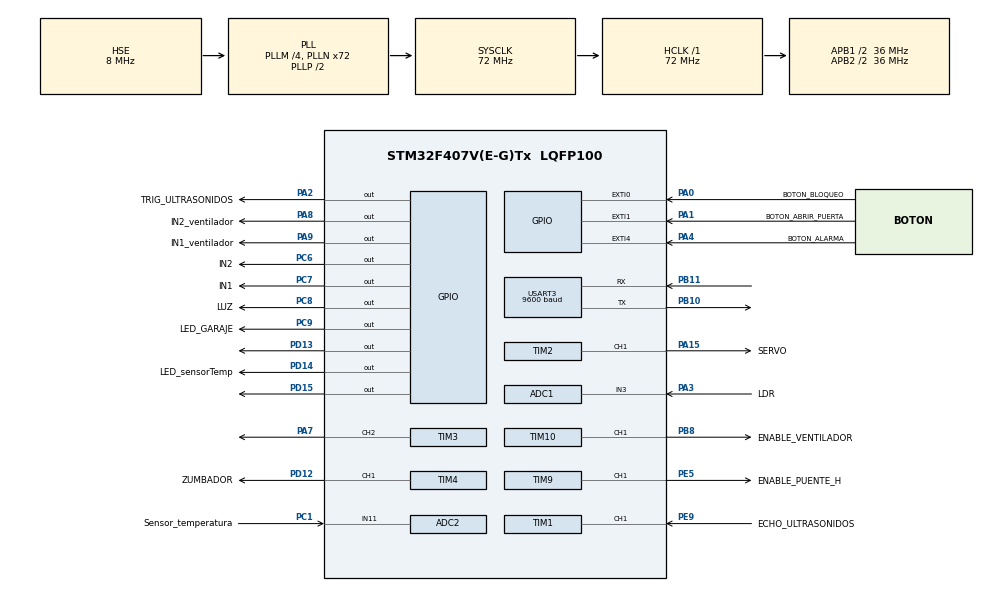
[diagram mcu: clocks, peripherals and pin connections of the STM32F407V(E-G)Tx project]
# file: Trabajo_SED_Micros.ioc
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ADC1.Channel-0\#ChannelRegularConversion=ADC_CHANNEL_3
ADC1.NbrOfConversionFlag=1
ADC1.Rank-0\#ChannelRegularConversion=1
ADC1.Resolution=ADC_RESOLUTION_8B
ADC1.SamplingTime-0\#ChannelRegularConversion=ADC_SAMPLETIME_3CYCLES
ADC1.master=1
ADC2.Channel-0\#ChannelRegularConversion=ADC_CHANNEL_11
ADC2.NbrOfConversionFlag=1
ADC2.Rank-0\#ChannelRegularConversion=1
ADC2.Resolution=ADC_RESOLUTION_8B
ADC2.SamplingTime-0\#ChannelRegularConversion=ADC_SAMPLETIME_3CYCLES
Dma.Request0=USART3_RX
Dma.USART3_RX.0.Direction=DMA_PERIPH_TO_MEMORY
Dma.USART3_RX.0.FIFOMode=DMA_FIFOMODE_DISABLE
Dma.USART3_RX.0.Instance=DMA1_Stream1
Dma.USART3_RX.0.MemDataAlignment=DMA_MDATAALIGN_BYTE
Dma.USART3_RX.0.MemInc=DMA_MINC_ENABLE
Dma.USART3_RX.0.Mode=DMA_NORMAL
Dma.USART3_RX.0.PeriphDataAlignment=DMA_PDATAALIGN_BYTE
Dma.USART3_RX.0.PeriphInc=DMA_PINC_DISABLE
Dma.USART3_RX.0.Priority=DMA_PRIORITY_LOW
Mcu.Family=STM32F4
Mcu.Name=STM32F407V(E-G)Tx
Mcu.Package=LQFP100
NVIC.ADC_IRQn=true\:0\:0\:false\:false\:true\:true\:true
NVIC.DMA1_Stream1_IRQn=true\:0\:0\:false\:false\:true\:false\:true
NVIC.EXTI0_IRQn=true\:0\:0\:false\:false\:true\:true\:true
NVIC.EXTI1_IRQn=true\:0\:0\:false\:false\:true\:true\:true
NVIC.EXTI4_IRQn=true\:0\:0\:false\:false\:true\:true\:true
NVIC.PriorityGroup=NVIC_PRIORITYGROUP_0
NVIC.TIM1_CC_IRQn=true\:0\:0\:false\:false\:true\:true\:true
NVIC.TIM2_IRQn=true\:0\:0\:false\:false\:true\:true\:true
NVIC.USART3_IRQn=true\:0\:0\:false\:false\:true\:true\:true
PA0-WKUP.GPIO_Label=BOTON_BLOQUEO
PA0-WKUP.Signal=GPXTI0
PA1.GPIO_Label=BOTON_ABRIR_PUERTA
PA1.Signal=GPXTI1
PA15.GPIO_Label=SERVO
PA15.Signal=S_TIM2_CH1_ETR
PA2.GPIO_Label=TRIG_ULTRASONIDOS
PA2.Signal=GPIO_Output
PA3.GPIO_Label=LDR
PA3.Signal=ADCx_IN3
PA4.GPIO_Label=BOTON_ALARMA
PA4.Signal=GPXTI4
PA7.Signal=S_TIM3_CH2
PA8.GPIO_Label=IN2_ventilador
PA8.Signal=GPIO_Output
PA9.GPIO_Label=IN1_ventilador
PA9.Signal=GPIO_Output
PB10.Mode=Asynchronous
PB10.Signal=USART3_TX
PB11.Mode=Asynchronous
PB11.Signal=USART3_RX
PB8.GPIO_Label=ENABLE_VENTILADOR
PB8.Signal=S_TIM10_CH1
PC1.GPIO_Label=Sensor_temperatura
PC1.Signal=ADCx_IN11
PC6.GPIO_Label=IN2
PC6.Signal=GPIO_Output
PC7.GPIO_Label=IN1
PC7.Signal=GPIO_Output
PC8.GPIO_Label=LUZ
PC8.Signal=GPIO_Output
PC9.GPIO_Label=LED_GARAJE
PC9.Signal=GPIO_Output
PD12.GPIO_Label=ZUMBADOR
PD12.Signal=S_TIM4_CH1
PD13.Signal=GPIO_Output
PD14.GPIO_Label=LED_sensorTemp
PD14.Signal=GPIO_Output
PD15.Signal=GPIO_Output
PE5.GPIO_Label=ENABLE_PUENTE_H
PE5.Signal=S_TIM9_CH1
PE9.GPIO_Label=ECHO_ULTRASONIDOS
PE9.Signal=S_TIM1_CH1
PH0-OSC_IN.Mode=HSE-External-Oscillator
PH0-OSC_IN.Signal=RCC_OSC_IN
PH1-OSC_OUT.Mode=HSE-External-Oscillator
PH1-OSC_OUT.Signal=RCC_OSC_OUT
ProjectManager.HeapSize=0x200
ProjectManager.StackSize=0x400
ProjectManager.TargetToolchain=STM32CubeIDE
RCC.48MHZClocksFreq_Value=20571428.57142857
RCC.AHBFreq_Value=72000000
RCC.APB1CLKDivider=RCC_HCLK_DIV2
RCC.APB1Freq_Value=36000000
RCC.APB1TimFreq_Value=72000000
RCC.APB2CLKDivider=RCC_HCLK_DIV2
RCC.APB2Freq_Value=36000000
RCC.APB2TimFreq_Value=72000000
RCC.CortexFreq_Value=72000000
RCC.HCLKFreq_Value=72000000
RCC.HSE_VALUE=8000000
RCC.HSI_VALUE=16000000
RCC.LSE_VALUE=32768
RCC.PLLM=4
RCC.PLLN=72
RCC.PLLQ=7
RCC.PLLSourceVirtual=RCC_PLLSOURCE_HSE
RCC.SYSCLKFreq_VALUE=72000000
RCC.SYSCLKSource=RCC_SYSCLKSOURCE_PLLCLK
RCC.VCOOutputFreq_Value=144000000
SH.ADCx_IN11.0=ADC2_IN11,IN11
SH.ADCx_IN3.0=ADC1_IN3,IN3
SH.S_TIM10_CH1.0=TIM10_CH1,PWM Generation1 CH1
SH.S_TIM1_CH1.0=TIM1_CH1,Input_Capture1_from_TI1
SH.S_TIM2_CH1_ETR.0=TIM2_CH1,PWM Generation1 CH1
SH.S_TIM3_CH2.0=TIM3_CH2,PWM Generation2 CH2
SH.S_TIM4_CH1.0=TIM4_CH1,PWM Generation1 CH1
SH.S_TIM9_CH1.0=TIM9_CH1,PWM Generation1 CH1
TIM1.Channel-Input_Capture1_from_TI1=TIM_CHANNEL_1
TIM1.Period=20000-1
TIM1.Prescaler=72-1
TIM10.Channel=TIM_CHANNEL_1
TIM10.Period=2000
TIM10.Prescaler=72-1
TIM2.Channel-PWM\ Generation1\ CH1=TIM_CHANNEL_1
TIM2.Period=20000
TIM2.Prescaler=72-1
TIM3.Channel-PWM\ Generation2\ CH2=TIM_CHANNEL_2
TIM3.Period=20000
TIM3.Prescaler=72-1
TIM4.Channel-PWM\ Generation1\ CH1=TIM_CHANNEL_1
TIM4.Period=3922
TIM4.Prescaler=72-1
TIM9.Channel-PWM\ Generation1\ CH1=TIM_CHANNEL_1
TIM9.Period=2000
TIM9.Prescaler=72-1
USART3.BaudRate=9600
USART3.Mode=MODE_RX
USART3.VirtualMode=VM_ASYNC
VP_TIM10_VS_ClockSourceINT.Mode=Enable_Timer
VP_TIM2_VS_ClockSourceINT.Mode=Internal
VP_TIM4_VS_ClockSourceINT.Mode=Internal
board=STM32F407G-DISC1

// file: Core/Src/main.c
/* USER CODE END Header */
#include "Funciones.h"

void SystemClock_Config(void);
static void MX_GPIO_Init(void);
static void MX_TIM1_Init(void);
static void MX_TIM2_Init(void);
static void MX_ADC1_Init(void);
static void MX_TIM3_Init(void);
static void MX_DMA_Init(void);
static void MX_USART3_UART_Init(void);
static void MX_TIM4_Init(void);
static void MX_TIM9_Init(void);
static void MX_ADC2_Init(void);
static void MX_TIM10_Init(void);

/* USER CODE BEGIN 0 */
int main(void)
{

  /* MCU Configuration--------------------------------------------------------*/

  /* Reset of all peripherals, Initializes the Flash interface and the Systick. */
  HAL_Init();

  /* Configure the system clock */
  SystemClock_Config();

  /* Initialize all configured peripherals */
  MX_GPIO_Init();
  MX_TIM1_Init();
  MX_TIM2_Init();
  MX_ADC1_Init();
  MX_TIM3_Init();
  MX_DMA_Init();
  MX_USART3_UART_Init();
  MX_TIM4_Init();
  MX_TIM9_Init();
  MX_ADC2_Init();
  MX_TIM10_Init();
  /* USER CODE BEGIN 2 */
  HAL_TIM_IC_Start_IT(&htim1, TIM_CHANNEL_1);
  HAL_TIM_PWM_Start(&htim2, TIM_CHANNEL_1);
  HAL_TIM_PWM_Start(&htim9, TIM_CHANNEL_1);
  HAL_TIM_PWM_Start(&htim10, TIM_CHANNEL_1);
  HAL_TIM_PWM_Start(&htim4,TIM_CHANNEL_1);
  HAL_UART_Receive_IT(&huart3, (uint8_t*)readBuf, 1);
 // HAL_ADC_Start_IT(&hadc1);
 // HAL_ADC_Start_IT(&hadc2);
  /* USER CODE END 2 */

  /* Infinite loop */
  while (1)
  {
    /* USER CODE BEGIN 3 */

	alarma();
	puerta();
	LDR();
	persianas();
	temperatura();
	ventilador();

  }
  /* USER CODE END 3 */
}

void SystemClock_Config(void)
{
  RCC_OscInitTypeDef RCC_OscInitStruct = {0};
  RCC_ClkInitTypeDef RCC_ClkInitStruct = {0};

  /** Configure the main internal regulator output voltage
  */
  __HAL_RCC_PWR_CLK_ENABLE();
  __HAL_PWR_VOLTAGESCALING_CONFIG(PWR_REGULATOR_VOLTAGE_SCALE1);
  /** Initializes the RCC Oscillators according to the specified parameters
  * in the RCC_OscInitTypeDef structure.
  */
  RCC_OscInitStruct.OscillatorType = RCC_OSCILLATORTYPE_HSE;
  RCC_OscInitStruct.HSEState = RCC_HSE_ON;
  RCC_OscInitStruct.PLL.PLLState = RCC_PLL_ON;
  RCC_OscInitStruct.PLL.PLLSource = RCC_PLLSOURCE_HSE;
  RCC_OscInitStruct.PLL.PLLM = 4;
  RCC_OscInitStruct.PLL.PLLN = 72;
  RCC_OscInitStruct.PLL.PLLP = RCC_PLLP_DIV2;
  RCC_OscInitStruct.PLL.PLLQ = 7;
  if (HAL_RCC_OscConfig(&RCC_OscInitStruct) != HAL_OK)
  {
    Error_Handler();
  }
  /** Initializes the CPU, AHB and APB buses clocks
  */
  RCC_ClkInitStruct.ClockType = RCC_CLOCKTYPE_HCLK|RCC_CLOCKTYPE_SYSCLK
                              |RCC_CLOCKTYPE_PCLK1|RCC_CLOCKTYPE_PCLK2;
  RCC_ClkInitStruct.SYSCLKSource = RCC_SYSCLKSOURCE_PLLCLK;
  RCC_ClkInitStruct.AHBCLKDivider = RCC_SYSCLK_DIV1;
  RCC_ClkInitStruct.APB1CLKDivider = RCC_HCLK_DIV2;
  RCC_ClkInitStruct.APB2CLKDivider = RCC_HCLK_DIV2;

  if (HAL_RCC_ClockConfig(&RCC_ClkInitStruct, FLASH_LATENCY_2) != HAL_OK)
  {
    Error_Handler();
  }
}

static void MX_ADC1_Init(void)
{

  ADC_ChannelConfTypeDef sConfig = {0};

  /** Configure the global features of the ADC (Clock, Resolution, Data Alignment and number of conversion)
  */
  hadc1.Instance = ADC1;
  hadc1.Init.ClockPrescaler = ADC_CLOCK_SYNC_PCLK_DIV2;
  hadc1.Init.Resolution = ADC_RESOLUTION_8B;
  hadc1.Init.ScanConvMode = DISABLE;
  hadc1.Init.ContinuousConvMode = DISABLE;
  hadc1.Init.DiscontinuousConvMode = DISABLE;
  hadc1.Init.ExternalTrigConvEdge = ADC_EXTERNALTRIGCONVEDGE_NONE;
  hadc1.Init.ExternalTrigConv = ADC_SOFTWARE_START;
  hadc1.Init.DataAlign = ADC_DATAALIGN_RIGHT;
  hadc1.Init.NbrOfConversion = 1;
  hadc1.Init.DMAContinuousRequests = DISABLE;
  hadc1.Init.EOCSelection = ADC_EOC_SINGLE_CONV;
  if (HAL_ADC_Init(&hadc1) != HAL_OK)
  {
    Error_Handler();
  }
  /** Configure for the selected ADC regular channel its corresponding rank in the sequencer and its sample time.
  */
  sConfig.Channel = ADC_CHANNEL_3;
  sConfig.Rank = 1;
  sConfig.SamplingTime = ADC_SAMPLETIME_3CYCLES;
  if (HAL_ADC_ConfigChannel(&hadc1, &sConfig) != HAL_OK)
  {
    Error_Handler();
  }

}

static void MX_ADC2_Init(void)
{

  ADC_ChannelConfTypeDef sConfig = {0};

  /** Configure the global features of the ADC (Clock, Resolution, Data Alignment and number of conversion)
  */
  hadc2.Instance = ADC2;
  hadc2.Init.ClockPrescaler = ADC_CLOCK_SYNC_PCLK_DIV2;
  hadc2.Init.Resolution = ADC_RESOLUTION_8B;
  hadc2.Init.ScanConvMode = DISABLE;
  hadc2.Init.ContinuousConvMode = DISABLE;
  hadc2.Init.DiscontinuousConvMode = DISABLE;
  hadc2.Init.ExternalTrigConvEdge = ADC_EXTERNALTRIGCONVEDGE_NONE;
  hadc2.Init.ExternalTrigConv = ADC_SOFTWARE_START;
  hadc2.Init.DataAlign = ADC_DATAALIGN_RIGHT;
  hadc2.Init.NbrOfConversion = 1;
  hadc2.Init.DMAContinuousRequests = DISABLE;
  hadc2.Init.EOCSelection = ADC_EOC_SINGLE_CONV;
  if (HAL_ADC_Init(&hadc2) != HAL_OK)
  {
    Error_Handler();
  }
  /** Configure for the selected ADC regular channel its corresponding rank in the sequencer and its sample time.
  */
  sConfig.Channel = ADC_CHANNEL_11;
  sConfig.Rank = 1;
  sConfig.SamplingTime = ADC_SAMPLETIME_3CYCLES;
  if (HAL_ADC_ConfigChannel(&hadc2, &sConfig) != HAL_OK)
  {
    Error_Handler();
  }

}

static void MX_TIM1_Init(void)
{

  TIM_MasterConfigTypeDef sMasterConfig = {0};
  TIM_IC_InitTypeDef sConfigIC = {0};

  htim1.Instance = TIM1;
  htim1.Init.Prescaler = 72-1;
  htim1.Init.CounterMode = TIM_COUNTERMODE_UP;
  htim1.Init.Period = 20000-1;
  htim1.Init.ClockDivision = TIM_CLOCKDIVISION_DIV1;
  htim1.Init.RepetitionCounter = 0;
  htim1.Init.AutoReloadPreload = TIM_AUTORELOAD_PRELOAD_DISABLE;
  if (HAL_TIM_IC_Init(&htim1) != HAL_OK)
  {
    Error_Handler();
  }
  sMasterConfig.MasterOutputTrigger = TIM_TRGO_RESET;
  sMasterConfig.MasterSlaveMode = TIM_MASTERSLAVEMODE_DISABLE;
  if (HAL_TIMEx_MasterConfigSynchronization(&htim1, &sMasterConfig) != HAL_OK)
  {
    Error_Handler();
  }
  sConfigIC.ICPolarity = TIM_INPUTCHANNELPOLARITY_RISING;
  sConfigIC.ICSelection = TIM_ICSELECTION_DIRECTTI;
  sConfigIC.ICPrescaler = TIM_ICPSC_DIV1;
  sConfigIC.ICFilter = 0;
  if (HAL_TIM_IC_ConfigChannel(&htim1, &sConfigIC, TIM_CHANNEL_1) != HAL_OK)
  {
    Error_Handler();
  }

}

static void MX_TIM2_Init(void)
{

  TIM_ClockConfigTypeDef sClockSourceConfig = {0};
  TIM_MasterConfigTypeDef sMasterConfig = {0};
  TIM_OC_InitTypeDef sConfigOC = {0};

  htim2.Instance = TIM2;
  htim2.Init.Prescaler = 72-1;
  htim2.Init.CounterMode = TIM_COUNTERMODE_UP;
  htim2.Init.Period = 20000;
  htim2.Init.ClockDivision = TIM_CLOCKDIVISION_DIV1;
  htim2.Init.AutoReloadPreload = TIM_AUTORELOAD_PRELOAD_DISABLE;
  if (HAL_TIM_Base_Init(&htim2) != HAL_OK)
  {
    Error_Handler();
  }
  sClockSourceConfig.ClockSource = TIM_CLOCKSOURCE_INTERNAL;
  if (HAL_TIM_ConfigClockSource(&htim2, &sClockSourceConfig) != HAL_OK)
  {
    Error_Handler();
  }
  if (HAL_TIM_PWM_Init(&htim2) != HAL_OK)
  {
    Error_Handler();
  }
  sMasterConfig.MasterOutputTrigger = TIM_TRGO_RESET;
  sMasterConfig.MasterSlaveMode = TIM_MASTERSLAVEMODE_DISABLE;
  if (HAL_TIMEx_MasterConfigSynchronization(&htim2, &sMasterConfig) != HAL_OK)
  {
    Error_Handler();
  }
  sConfigOC.OCMode = TIM_OCMODE_PWM1;
  sConfigOC.Pulse = 0;
  sConfigOC.OCPolarity = TIM_OCPOLARITY_HIGH;
  sConfigOC.OCFastMode = TIM_OCFAST_DISABLE;
  if (HAL_TIM_PWM_ConfigChannel(&htim2, &sConfigOC, TIM_CHANNEL_1) != HAL_OK)
  {
    Error_Handler();
  }
  HAL_TIM_MspPostInit(&htim2);

}

static void MX_TIM3_Init(void)
{

  TIM_MasterConfigTypeDef sMasterConfig = {0};
  TIM_OC_InitTypeDef sConfigOC = {0};

  htim3.Instance = TIM3;
  htim3.Init.Prescaler = 72-1;
  htim3.Init.CounterMode = TIM_COUNTERMODE_UP;
  htim3.Init.Period = 20000;
  htim3.Init.ClockDivision = TIM_CLOCKDIVISION_DIV1;
  htim3.Init.AutoReloadPreload = TIM_AUTORELOAD_PRELOAD_DISABLE;
  if (HAL_TIM_PWM_Init(&htim3) != HAL_OK)
  {
    Error_Handler();
  }
  sMasterConfig.MasterOutputTrigger = TIM_TRGO_RESET;
  sMasterConfig.MasterSlaveMode = TIM_MASTERSLAVEMODE_DISABLE;
  if (HAL_TIMEx_MasterConfigSynchronization(&htim3, &sMasterConfig) != HAL_OK)
  {
    Error_Handler();
  }
  sConfigOC.OCMode = TIM_OCMODE_PWM1;
  sConfigOC.Pulse = 0;
  sConfigOC.OCPolarity = TIM_OCPOLARITY_HIGH;
  sConfigOC.OCFastMode = TIM_OCFAST_DISABLE;
  if (HAL_TIM_PWM_ConfigChannel(&htim3, &sConfigOC, TIM_CHANNEL_2) != HAL_OK)
  {
    Error_Handler();
  }
  HAL_TIM_MspPostInit(&htim3);

}

static void MX_TIM4_Init(void)
{

  TIM_ClockConfigTypeDef sClockSourceConfig = {0};
  TIM_MasterConfigTypeDef sMasterConfig = {0};
  TIM_OC_InitTypeDef sConfigOC = {0};

  htim4.Instance = TIM4;
  htim4.Init.Prescaler = 72-1;
  htim4.Init.CounterMode = TIM_COUNTERMODE_UP;
  htim4.Init.Period = 3922;
  htim4.Init.ClockDivision = TIM_CLOCKDIVISION_DIV1;
  htim4.Init.AutoReloadPreload = TIM_AUTORELOAD_PRELOAD_DISABLE;
  if (HAL_TIM_Base_Init(&htim4) != HAL_OK)
  {
    Error_Handler();
  }
  sClockSourceConfig.ClockSource = TIM_CLOCKSOURCE_INTERNAL;
  if (HAL_TIM_ConfigClockSource(&htim4, &sClockSourceConfig) != HAL_OK)
  {
    Error_Handler();
  }
  if (HAL_TIM_PWM_Init(&htim4) != HAL_OK)
  {
    Error_Handler();
  }
  sMasterConfig.MasterOutputTrigger = TIM_TRGO_RESET;
  sMasterConfig.MasterSlaveMode = TIM_MASTERSLAVEMODE_DISABLE;
  if (HAL_TIMEx_MasterConfigSynchronization(&htim4, &sMasterConfig) != HAL_OK)
  {
    Error_Handler();
  }
  sConfigOC.OCMode = TIM_OCMODE_PWM1;
  sConfigOC.Pulse = 0;
  sConfigOC.OCPolarity = TIM_OCPOLARITY_HIGH;
  sConfigOC.OCFastMode = TIM_OCFAST_DISABLE;
  if (HAL_TIM_PWM_ConfigChannel(&htim4, &sConfigOC, TIM_CHANNEL_1) != HAL_OK)
  {
    Error_Handler();
  }
  HAL_TIM_MspPostInit(&htim4);

}

static void MX_TIM9_Init(void)
{

  TIM_OC_InitTypeDef sConfigOC = {0};

  htim9.Instance = TIM9;
  htim9.Init.Prescaler = 72-1;
  htim9.Init.CounterMode = TIM_COUNTERMODE_UP;
  htim9.Init.Period = 2000;
  htim9.Init.ClockDivision = TIM_CLOCKDIVISION_DIV1;
  htim9.Init.AutoReloadPreload = TIM_AUTORELOAD_PRELOAD_DISABLE;
  if (HAL_TIM_PWM_Init(&htim9) != HAL_OK)
  {
    Error_Handler();
  }
  sConfigOC.OCMode = TIM_OCMODE_PWM1;
  sConfigOC.Pulse = 0;
  sConfigOC.OCPolarity = TIM_OCPOLARITY_HIGH;
  sConfigOC.OCFastMode = TIM_OCFAST_DISABLE;
  if (HAL_TIM_PWM_ConfigChannel(&htim9, &sConfigOC, TIM_CHANNEL_1) != HAL_OK)
  {
    Error_Handler();
  }
  HAL_TIM_MspPostInit(&htim9);

}

static void MX_TIM10_Init(void)
{

  TIM_OC_InitTypeDef sConfigOC = {0};

  htim10.Instance = TIM10;
  htim10.Init.Prescaler = 72-1;
  htim10.Init.CounterMode = TIM_COUNTERMODE_UP;
  htim10.Init.Period = 2000;
  htim10.Init.ClockDivision = TIM_CLOCKDIVISION_DIV1;
  htim10.Init.AutoReloadPreload = TIM_AUTORELOAD_PRELOAD_DISABLE;
  if (HAL_TIM_Base_Init(&htim10) != HAL_OK)
  {
    Error_Handler();
  }
  if (HAL_TIM_PWM_Init(&htim10) != HAL_OK)
  {
    Error_Handler();
  }
  sConfigOC.OCMode = TIM_OCMODE_PWM1;
  sConfigOC.Pulse = 0;
  sConfigOC.OCPolarity = TIM_OCPOLARITY_HIGH;
  sConfigOC.OCFastMode = TIM_OCFAST_DISABLE;
  if (HAL_TIM_PWM_ConfigChannel(&htim10, &sConfigOC, TIM_CHANNEL_1) != HAL_OK)
  {
    Error_Handler();
  }
  HAL_TIM_MspPostInit(&htim10);

}

static void MX_USART3_UART_Init(void)
{

  huart3.Instance = USART3;
  huart3.Init.BaudRate = 9600;
  huart3.Init.WordLength = UART_WORDLENGTH_8B;
  huart3.Init.StopBits = UART_STOPBITS_1;
  huart3.Init.Parity = UART_PARITY_NONE;
  huart3.Init.Mode = UART_MODE_RX;
  huart3.Init.HwFlowCtl = UART_HWCONTROL_NONE;
  huart3.Init.OverSampling = UART_OVERSAMPLING_16;
  if (HAL_UART_Init(&huart3) != HAL_OK)
  {
    Error_Handler();
  }

}

static void MX_DMA_Init(void)
{

  /* DMA controller clock enable */
  __HAL_RCC_DMA1_CLK_ENABLE();

  /* DMA interrupt init */
  /* DMA1_Stream1_IRQn interrupt configuration */
  HAL_NVIC_SetPriority(DMA1_Stream1_IRQn, 0, 0);
  HAL_NVIC_EnableIRQ(DMA1_Stream1_IRQn);

}

static void MX_GPIO_Init(void)
{
  GPIO_InitTypeDef GPIO_InitStruct = {0};

  /* GPIO Ports Clock Enable */
  __HAL_RCC_GPIOE_CLK_ENABLE();
  __HAL_RCC_GPIOH_CLK_ENABLE();
  __HAL_RCC_GPIOC_CLK_ENABLE();
  __HAL_RCC_GPIOA_CLK_ENABLE();
  __HAL_RCC_GPIOB_CLK_ENABLE();
  __HAL_RCC_GPIOD_CLK_ENABLE();

  /*Configure GPIO pin Output Level */
  HAL_GPIO_WritePin(GPIOA, TRIG_ULTRASONIDOS_Pin|IN2_ventilador_Pin|IN1_ventilador_Pin, GPIO_PIN_RESET);

  /*Configure GPIO pin Output Level */
  HAL_GPIO_WritePin(GPIOD, GPIO_PIN_13|LED_sensorTemp_Pin|GPIO_PIN_15, GPIO_PIN_RESET);

  /*Configure GPIO pin Output Level */
  HAL_GPIO_WritePin(GPIOC, IN2_Pin|IN1_Pin|LUZ_Pin|LED_GARAJE_Pin, GPIO_PIN_RESET);

  /*Configure GPIO pins : BOTON_BLOQUEO_Pin BOTON_ABRIR_PUERTA_Pin BOTON_ALARMA_Pin */
  GPIO_InitStruct.Pin = BOTON_BLOQUEO_Pin|BOTON_ABRIR_PUERTA_Pin|BOTON_ALARMA_Pin;
  GPIO_InitStruct.Mode = GPIO_MODE_IT_RISING;
  GPIO_InitStruct.Pull = GPIO_NOPULL;
  HAL_GPIO_Init(GPIOA, &GPIO_InitStruct);

  /*Configure GPIO pins : TRIG_ULTRASONIDOS_Pin IN2_ventilador_Pin IN1_ventilador_Pin */
  GPIO_InitStruct.Pin = TRIG_ULTRASONIDOS_Pin|IN2_ventilador_Pin|IN1_ventilador_Pin;
  GPIO_InitStruct.Mode = GPIO_MODE_OUTPUT_PP;
  GPIO_InitStruct.Pull = GPIO_NOPULL;
  GPIO_InitStruct.Speed = GPIO_SPEED_FREQ_LOW;
  HAL_GPIO_Init(GPIOA, &GPIO_InitStruct);

  /*Configure GPIO pins : PD13 LED_sensorTemp_Pin PD15 */
  GPIO_InitStruct.Pin = GPIO_PIN_13|LED_sensorTemp_Pin|GPIO_PIN_15;
  GPIO_InitStruct.Mode = GPIO_MODE_OUTPUT_PP;
  GPIO_InitStruct.Pull = GPIO_NOPULL;
  GPIO_InitStruct.Speed = GPIO_SPEED_FREQ_LOW;
  HAL_GPIO_Init(GPIOD, &GPIO_InitStruct);

  /*Configure GPIO pins : IN2_Pin IN1_Pin LUZ_Pin LED_GARAJE_Pin */
  GPIO_InitStruct.Pin = IN2_Pin|IN1_Pin|LUZ_Pin|LED_GARAJE_Pin;
  GPIO_InitStruct.Mode = GPIO_MODE_OUTPUT_PP;
  GPIO_InitStruct.Pull = GPIO_NOPULL;
  GPIO_InitStruct.Speed = GPIO_SPEED_FREQ_LOW;
  HAL_GPIO_Init(GPIOC, &GPIO_InitStruct);

  /* EXTI interrupt init*/
  HAL_NVIC_SetPriority(EXTI0_IRQn, 0, 0);
  HAL_NVIC_EnableIRQ(EXTI0_IRQn);

  HAL_NVIC_SetPriority(EXTI1_IRQn, 0, 0);
  HAL_NVIC_EnableIRQ(EXTI1_IRQn);

  HAL_NVIC_SetPriority(EXTI4_IRQn, 0, 0);
  HAL_NVIC_EnableIRQ(EXTI4_IRQn);

}

void Error_Handler(void)
{
  __disable_irq();
  while (1)
  {
  }
}
